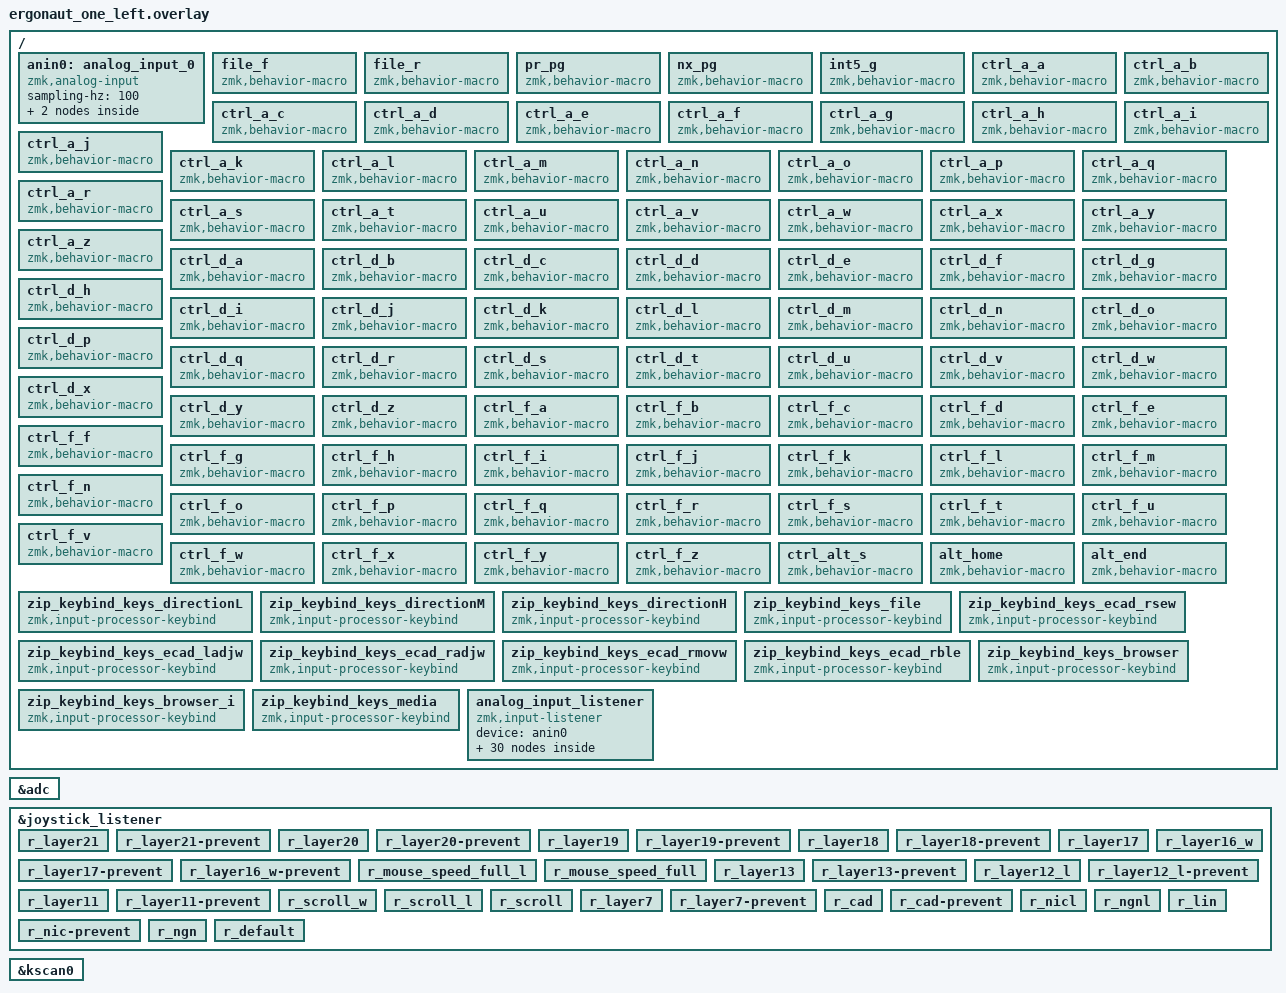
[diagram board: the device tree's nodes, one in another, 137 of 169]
/*
 * Copyright (c) 2020 The ZMK Contributors
 *
 * SPDX-License-Identifier: MIT
 */

#include "ergonaut_one.dtsi"
#include <zephyr/dt-bindings/input/input-event-codes.h>
#include <input/processors.dtsi>
#include <dt-bindings/zmk/input_transform.h>
#include <dt-bindings/zmk/keys.h>
#include <behaviors/naginata.dtsi>
#include <dt-bindings/zmk/pointing.h> // pointing.h はマウス機能に必要です
// #include <behaviors/input_gestures_accel.dtsi>

#define ZMK_POINTING_DEFAULT_MOVE_VAL 600   // default: 600
#define ZMK_POINTING_DEFAULT_SCRL_VAL 10    // default: 10

#define QWE 0
#define NGN 1
#define NIC 2
#define LIN 3
#define NGNL 4
#define NICL 5
#define CAD 6
#define WIN 7
#define LWR 8
#define LWRL 9
#define LWRW 10
#define RSE 11
#define RSEL 12
#define RSEW 13
#define ADJ 14
#define ADJL 15
#define ADJW 16
#define MOV 17
#define MOVL 18
#define MOVW 19
#define NUM 20
#define BLE 21

&adc {
	status = "okay";
};

/ {
	// 左のジョイスティック（マウスカーソル移動用）
	anin0: analog_input_0 {
		compatible = "zmk,analog-input";
		sampling-hz = <100>;
		y-ch {
			io-channels = <&adc 0>; // Y軸がADCチャンネル0に接続
			mv-mid = <1555>; // Y軸のニュートラル（中央）でのミリボルト値
			mv-min-max = <2615>; // Y軸の最小/最大ミリボルト範囲
			mv-deadzone = <88>; // Y軸のデッドゾーン（感度を調整）
			scale-multiplier = <1>; // スケーリングの乗数
			scale-divisor = <50>; // スケーリングの除数
			#invert; // Y軸の入力を反転
			evt-type = <INPUT_EV_REL>; // 相対イベントタイプ
			input-code = <INPUT_REL_Y>; // Y軸の動きをマウスのY軸（垂直）にマッピング
		};
		x-ch {
			io-channels = <&adc 1>; // X軸がADCチャンネル1に接続
			mv-mid = <1576>; // X軸のニュートラル（中央）でのミリボルト値
			mv-min-max = <2460>; // X軸の最小/最大ミリボルト範囲
			mv-deadzone = <88>; // X軸のデッドゾーン
			scale-multiplier = <1>;
			scale-divisor = <50>;
			invert; // X軸の入力を反転
			evt-type = <INPUT_EV_REL>;
			input-code = <INPUT_REL_X>; // X軸の動きをマウスのX軸（水平）にマッピング
			#report-on-change-only;
		};
	};
	
	file_f: file_f { // ファイルの切り替え正
		compatible = "zmk,behavior-macro";
		wait-ms = <40>;
		tap-ms = <40>;
		#binding-cells = <0>;
		bindings
			= <&macro_press &kp LCTRL>
			, <&macro_tap &kp F6>
			, <&macro_release &kp LCTRL>
			;
    };
	file_r: file_r { // ファイルの切り替え逆
		compatible = "zmk,behavior-macro";
		wait-ms = <40>;
		tap-ms = <40>;
		#binding-cells = <0>;
		bindings
			= <&macro_press &kp LSHFT>
			, <&macro_press &kp LCTRL>
			, <&macro_tap &kp F6>
			, <&macro_release &kp LCTRL>
			, <&macro_release &kp LSHFT>
			;
    };
	pr_pg: pr_pg { // 前ページ切り替え
		compatible = "zmk,behavior-macro";
		wait-ms = <40>;
		tap-ms = <40>;
		#binding-cells = <0>;
		bindings
			= <&macro_press &kp LSHFT>
			, <&macro_tap &kp F5>
			, <&macro_release &kp LSHFT>
			;
    };
	nx_pg: nx_pg { // 次ページ切り替え
		compatible = "zmk,behavior-macro";
		wait-ms = <40>;
		tap-ms = <40>;
		#binding-cells = <0>;
		bindings
			= <&macro_press &kp LSHFT>
			, <&macro_tap &kp F6>
			, <&macro_release &kp LSHFT>
			;
    };
	int5_g: int5_g { // 端点再設定(AHK)
		compatible = "zmk,behavior-macro";
		#binding-cells = <0>;
		bindings
			= <&macro_press &kp INT5>
			, <&macro_wait_time 40>
			, <&macro_tap &kp G>
			, <&macro_wait_time 40>
			, <&macro_release &kp INT5>
			;
    };

	// ここから下はECAD用マクロ定義
        // =========================================================================
        // --- 2. Ctrl + A (<Key1> + Ctrl + A) ---
        // =========================================================================
        
	// Ctrl + A, A: 回転
	ctrl_a_a: ctrl_a_a {
		compatible = "zmk,behavior-macro";
		#binding-cells = <0>;
		bindings
			= <&macro_press &kp LCTRL>
			, <&macro_tap &kp A>, <&macro_release &kp LCTRL>
			, <&macro_tap &kp A>
			;
	};

	// Ctrl + A, B: 長方形(サイズ)
	ctrl_a_b: ctrl_a_b {
		compatible = "zmk,behavior-macro";
		#binding-cells = <0>;
		bindings
			= <&macro_press &kp LCTRL>
			, <&macro_tap &kp A>, <&macro_release &kp LCTRL>
			, <&macro_tap &kp B>
			;
	};

	// Ctrl + A, C: コピー
	ctrl_a_c: ctrl_a_c {
		compatible = "zmk,behavior-macro";
		#binding-cells = <0>;
		bindings
			= <&macro_press &kp LCTRL>
			, <&macro_tap &kp A>, <&macro_release &kp LCTRL>
			, <&macro_tap &kp C>
			;
	};

	// Ctrl + A, D: 補助線削除
	ctrl_a_d: ctrl_a_d {
		compatible = "zmk,behavior-macro";
		#binding-cells = <0>;
		bindings
			= <&macro_press &kp LCTRL>
			, <&macro_tap &kp A>, <&macro_release &kp LCTRL>
			, <&macro_tap &kp D>
			;
	};

	// Ctrl + A, E: 文字種別変更
	ctrl_a_e: ctrl_a_e {
		compatible = "zmk,behavior-macro";
		#binding-cells = <0>;
		bindings
			= <&macro_press &kp LCTRL>
			, <&macro_tap &kp A>, <&macro_release &kp LCTRL>
			, <&macro_tap &kp E>
			;
	};

	// Ctrl + A, F: 多相結線
	ctrl_a_f: ctrl_a_f {
		compatible = "zmk,behavior-macro";
		#binding-cells = <0>;
		bindings
			= <&macro_press &kp LCTRL>
			, <&macro_tap &kp A>, <&macro_release &kp LCTRL>
			, <&macro_tap &kp F>
			;
	};

	// Ctrl + A, G: 図形グループ化解除
	ctrl_a_g: ctrl_a_g {
		compatible = "zmk,behavior-macro";
		#binding-cells = <0>;
		bindings
			= <&macro_press &kp LCTRL>
			, <&macro_tap &kp A>, <&macro_release &kp LCTRL>
			, <&macro_tap &kp G>
			;
	};

	// Ctrl + A, H: 文字列置換
	ctrl_a_h: ctrl_a_h {
		compatible = "zmk,behavior-macro";
		#binding-cells = <0>;
		bindings
			= <&macro_press &kp LCTRL>
			, <&macro_tap &kp A>, <&macro_release &kp LCTRL>
			, <&macro_tap &kp H>
			;
	};

	// Ctrl + A, I: 連続寸法線
	ctrl_a_i: ctrl_a_i {
		compatible = "zmk,behavior-macro";
		#binding-cells = <0>;
		bindings
			= <&macro_press &kp LCTRL>
			, <&macro_tap &kp A>, <&macro_release &kp LCTRL>
			, <&macro_tap &kp I>
			;
	};

	// Ctrl + A, J: 図面管理情報
	ctrl_a_j: ctrl_a_j {
		compatible = "zmk,behavior-macro";
		#binding-cells = <0>;
		bindings
			= <&macro_press &kp LCTRL>
			, <&macro_tap &kp A>, <&macro_release &kp LCTRL>
			, <&macro_tap &kp J>
			;
	};

	// Ctrl + A, K: コメント
	ctrl_a_k: ctrl_a_k {
		compatible = "zmk,behavior-macro";
		#binding-cells = <0>;
		bindings
			= <&macro_press &kp LCTRL>
			, <&macro_tap &kp A>, <&macro_release &kp LCTRL>
			, <&macro_tap &kp K>
			;
	};

	// Ctrl + A, L: 直線(中心線)
	ctrl_a_l: ctrl_a_l {
		compatible = "zmk,behavior-macro";
		#binding-cells = <0>;
		bindings
			= <&macro_press &kp LCTRL>
			, <&macro_tap &kp A>, <&macro_release &kp LCTRL>
			, <&macro_tap &kp L>
			;
	};

	// Ctrl + A, M: 上下中央間隔揃え
	ctrl_a_m: ctrl_a_m {
		compatible = "zmk,behavior-macro";
		#binding-cells = <0>;
		bindings
			= <&macro_press &kp LCTRL>
			, <&macro_tap &kp A>, <&macro_release &kp LCTRL>
			, <&macro_tap &kp M>
			;
	};

	// Ctrl + A, N: 自動線番範囲選択
	ctrl_a_n: ctrl_a_n {
		compatible = "zmk,behavior-macro";
		#binding-cells = <0>;
		bindings
			= <&macro_press &kp LCTRL>
			, <&macro_tap &kp A>, <&macro_release &kp LCTRL>
			, <&macro_tap &kp N>
			, <&macro_wait_time 80>
			, <&macro_tap &kp TAB>
			, <&macro_wait_time 50>
			, <&macro_tap &kp TAB>
			, <&macro_wait_time 50>
			, <&macro_tap &kp TAB>
			;
	};

	// Ctrl + A, O: 図形要素分解
	ctrl_a_o: ctrl_a_o {
		compatible = "zmk,behavior-macro";
		#binding-cells = <0>;
		bindings
			= <&macro_press &kp LCTRL>
			, <&macro_tap &kp A>, <&macro_release &kp LCTRL>
			, <&macro_tap &kp O>
			;
	};

	// Ctrl + A, P: ページ編集
	ctrl_a_p: ctrl_a_p {
		compatible = "zmk,behavior-macro";
		#binding-cells = <0>;
		bindings
			= <&macro_press &kp LCTRL>
			, <&macro_tap &kp A>, <&macro_release &kp LCTRL>
			, <&macro_tap &kp P>
			;
	};

	// Ctrl + A, Q: 円(中心)
	ctrl_a_q: ctrl_a_q {
		compatible = "zmk,behavior-macro";
		#binding-cells = <0>;
		bindings
			= <&macro_press &kp LCTRL>
			, <&macro_tap &kp A>, <&macro_release &kp LCTRL>
			, <&macro_tap &kp Q>
			;
	};

	// Ctrl + A, R: Ｒ枠変更
	ctrl_a_r: ctrl_a_r {
		compatible = "zmk,behavior-macro";
		#binding-cells = <0>;
		bindings
			= <&macro_press &kp LCTRL>
			, <&macro_tap &kp A>, <&macro_release &kp LCTRL>
			, <&macro_tap &kp R>
			;
	};

	// Ctrl + A, S: シンボル置換
	ctrl_a_s: ctrl_a_s {
		compatible = "zmk,behavior-macro";
		#binding-cells = <0>;
		bindings
			= <&macro_press &kp LCTRL>
			, <&macro_tap &kp A>, <&macro_release &kp LCTRL>
			, <&macro_tap &kp S>
			;
	};

	// Ctrl + A, T: 文章
	ctrl_a_t: ctrl_a_t {
		compatible = "zmk,behavior-macro";
		#binding-cells = <0>;
		bindings
			= <&macro_press &kp LCTRL>
			, <&macro_tap &kp A>, <&macro_release &kp LCTRL>
			, <&macro_tap &kp T>
			;
	};

	// Ctrl + A, U: 連続寸法線削除
	ctrl_a_u: ctrl_a_u {
		compatible = "zmk,behavior-macro";
		#binding-cells = <0>;
		bindings
			= <&macro_press &kp LCTRL>
			, <&macro_tap &kp A>, <&macro_release &kp LCTRL>
			, <&macro_tap &kp U>
			;
	};

	// Ctrl + A, V: 貼り付け
	ctrl_a_v: ctrl_a_v {
		compatible = "zmk,behavior-macro";
		#binding-cells = <0>;
		bindings
			= <&macro_press &kp LCTRL>
			, <&macro_tap &kp A>, <&macro_release &kp LCTRL>
			, <&macro_tap &kp V>
			;
	};

	// Ctrl + A, W: 渡りページ編集
	ctrl_a_w: ctrl_a_w {
		compatible = "zmk,behavior-macro";
		#binding-cells = <0>;
		bindings
			= <&macro_press &kp LCTRL>
			, <&macro_tap &kp A>, <&macro_release &kp LCTRL>
			, <&macro_tap &kp W>
			;
	};

	// Ctrl + A, X: 範囲切断
	ctrl_a_x: ctrl_a_x {
		compatible = "zmk,behavior-macro";
		#binding-cells = <0>;
		bindings
			= <&macro_press &kp LCTRL>
			, <&macro_tap &kp A>, <&macro_release &kp LCTRL>
			, <&macro_tap &kp X>
			;
	};

	// Ctrl + A, Y: シンボルレイヤ変更
	ctrl_a_y: ctrl_a_y {
		compatible = "zmk,behavior-macro";
		#binding-cells = <0>;
		bindings
			= <&macro_press &kp LCTRL>
			, <&macro_tap &kp A>, <&macro_release &kp LCTRL>
			, <&macro_tap &kp Y>
			;
	};

	// Ctrl + A, Z: フォーマット情報
	ctrl_a_z: ctrl_a_z {
		compatible = "zmk,behavior-macro";
		#binding-cells = <0>;
		bindings
			= <&macro_press &kp LCTRL>
			, <&macro_tap &kp A>, <&macro_release &kp LCTRL>
			, <&macro_tap &kp Z>
			;
	};


	// =========================================================================
	// --- 3. Ctrl + D (<Key1> + Ctrl + D) ---
	// =========================================================================

	// Ctrl + D, A: 拡大・縮小
	ctrl_d_a: ctrl_d_a {
		compatible = "zmk,behavior-macro";
		#binding-cells = <0>;
		bindings
			= <&macro_press &kp LCTRL>
			, <&macro_tap &kp D>, <&macro_release &kp LCTRL>
			, <&macro_tap &kp A>
			;
	};

	// Ctrl + D, B: 面取り
	ctrl_d_b: ctrl_d_b {
		compatible = "zmk,behavior-macro";
		#binding-cells = <0>;
		bindings
			= <&macro_press &kp LCTRL>
			, <&macro_tap &kp D>, <&macro_release &kp LCTRL>
			, <&macro_tap &kp B>
			;
	};

	// Ctrl + D, C: 円弧(中心)
	ctrl_d_c: ctrl_d_c {
		compatible = "zmk,behavior-macro";
		#binding-cells = <0>;
		bindings
			= <&macro_press &kp LCTRL>
			, <&macro_tap &kp D>, <&macro_release &kp LCTRL>
			, <&macro_tap &kp C>
			;
	};

	// Ctrl + D, D: 補助線全削除
	ctrl_d_d: ctrl_d_d {
		compatible = "zmk,behavior-macro";
		#binding-cells = <0>;
		bindings
			= <&macro_press &kp LCTRL>
			, <&macro_tap &kp D>, <&macro_release &kp LCTRL>
			, <&macro_tap &kp D>
			;
	};

	// Ctrl + D, E: 文章修正
	ctrl_d_e: ctrl_d_e {
		compatible = "zmk,behavior-macro";
		#binding-cells = <0>;
		bindings
			= <&macro_press &kp LCTRL>
			, <&macro_tap &kp D>, <&macro_release &kp LCTRL>
			, <&macro_tap &kp E>
			;
	};

	// Ctrl + D, F: ツイスト線
	ctrl_d_f: ctrl_d_f {
		compatible = "zmk,behavior-macro";
		#binding-cells = <0>;
		bindings
			= <&macro_press &kp LCTRL>
			, <&macro_tap &kp D>, <&macro_release &kp LCTRL>
			, <&macro_tap &kp F>
			;
	};

	// Ctrl + D, G: 図形配列
	ctrl_d_g: ctrl_d_g {
		compatible = "zmk,behavior-macro";
		#binding-cells = <0>;
		bindings
			= <&macro_press &kp LCTRL>
			, <&macro_tap &kp D>, <&macro_release &kp LCTRL>
			, <&macro_tap &kp G>
			;
	};

	// Ctrl + D, H: 文字列検索
	ctrl_d_h: ctrl_d_h {
		compatible = "zmk,behavior-macro";
		#binding-cells = <0>;
		bindings
			= <&macro_press &kp LCTRL>
			, <&macro_tap &kp D>, <&macro_release &kp LCTRL>
			, <&macro_tap &kp H>
			;
	};

	// Ctrl + D, I: 寸法線グループ化解除
	ctrl_d_i: ctrl_d_i {
		compatible = "zmk,behavior-macro";
		#binding-cells = <0>;
		bindings
			= <&macro_press &kp LCTRL>
			, <&macro_tap &kp D>, <&macro_release &kp LCTRL>
			, <&macro_tap &kp I>
			;
	};

	// Ctrl + D, J: ページ管理情報
	ctrl_d_j: ctrl_d_j {
		compatible = "zmk,behavior-macro";
		#binding-cells = <0>;
		bindings
			= <&macro_press &kp LCTRL>
			, <&macro_tap &kp D>, <&macro_release &kp LCTRL>
			, <&macro_tap &kp J>
			;
	};

	// Ctrl + D, K: 目次作成
	ctrl_d_k: ctrl_d_k {
		compatible = "zmk,behavior-macro";
		#binding-cells = <0>;
		bindings
			= <&macro_press &kp LCTRL>
			, <&macro_tap &kp D>, <&macro_release &kp LCTRL>
			, <&macro_tap &kp K>
			;
	};

	// Ctrl + D, L: 平行補助線入力
	ctrl_d_l: ctrl_d_l {
		compatible = "zmk,behavior-macro";
		#binding-cells = <0>;
		bindings
			= <&macro_press &kp LCTRL>
			, <&macro_tap &kp D>, <&macro_release &kp LCTRL>
			, <&macro_tap &kp L>
			;
	};

	// Ctrl + D, M: 左右中央間隔揃え
	ctrl_d_m: ctrl_d_m {
		compatible = "zmk,behavior-macro";
		#binding-cells = <0>;
		bindings
			= <&macro_press &kp LCTRL>
			, <&macro_tap &kp D>, <&macro_release &kp LCTRL>
			, <&macro_tap &kp M>
			;
	};

	// Ctrl + D, N: 三相線番
	ctrl_d_n: ctrl_d_n {
		compatible = "zmk,behavior-macro";
		#binding-cells = <0>;
		bindings
			= <&macro_press &kp LCTRL>
			, <&macro_tap &kp D>, <&macro_release &kp LCTRL>
			, <&macro_tap &kp N>
			;
	};

	// Ctrl + D, O: 図形要素分割
	ctrl_d_o: ctrl_d_o {
		compatible = "zmk,behavior-macro";
		#binding-cells = <0>;
		bindings
			= <&macro_press &kp LCTRL>
			, <&macro_tap &kp D>, <&macro_release &kp LCTRL>
			, <&macro_tap &kp O>
			;
	};

	// Ctrl + D, P: 印刷情報
	ctrl_d_p: ctrl_d_p {
		compatible = "zmk,behavior-macro";
		#binding-cells = <0>;
		bindings
			= <&macro_press &kp LCTRL>
			, <&macro_tap &kp D>, <&macro_release &kp LCTRL>
			, <&macro_tap &kp P>
			;
	};

	// Ctrl + D, Q: 雲形
	ctrl_d_q: ctrl_d_q {
		compatible = "zmk,behavior-macro";
		#binding-cells = <0>;
		bindings
			= <&macro_press &kp LCTRL>
			, <&macro_tap &kp D>, <&macro_release &kp LCTRL>
			, <&macro_tap &kp Q>
			;
	};

	// Ctrl + D, R: 接続点
	ctrl_d_r: ctrl_d_r {
		compatible = "zmk,behavior-macro";
		#binding-cells = <0>;
		bindings
			= <&macro_press &kp LCTRL>
			, <&macro_tap &kp D>, <&macro_release &kp LCTRL>
			, <&macro_tap &kp R>
			;
	};

	// Ctrl + D, S: DXF/DWGファイル入力
	ctrl_d_s: ctrl_d_s {
		compatible = "zmk,behavior-macro";
		#binding-cells = <0>;
		bindings
			= <&macro_press &kp LCTRL>
			, <&macro_tap &kp D>, <&macro_release &kp LCTRL>
			, <&macro_tap &kp S>
			;
	};

	// Ctrl + D, T: 製品情報
	ctrl_d_t: ctrl_d_t {
		compatible = "zmk,behavior-macro";
		#binding-cells = <0>;
		bindings
			= <&macro_press &kp LCTRL>
			, <&macro_tap &kp D>, <&macro_release &kp LCTRL>
			, <&macro_tap &kp T>
			;
	};

	// Ctrl + D, U: 寸法線グループ化
	ctrl_d_u: ctrl_d_u {
		compatible = "zmk,behavior-macro";
		#binding-cells = <0>;
		bindings
			= <&macro_press &kp LCTRL>
			, <&macro_tap &kp D>, <&macro_release &kp LCTRL>
			, <&macro_tap &kp U>
			;
	};

	// Ctrl + D, V: 盤枠線(矩形)
	ctrl_d_v: ctrl_d_v {
		compatible = "zmk,behavior-macro";
		#binding-cells = <0>;
		bindings
			= <&macro_press &kp LCTRL>
			, <&macro_tap &kp D>, <&macro_release &kp LCTRL>
			, <&macro_tap &kp V>
			;
	};

	// Ctrl + D, W: 一時補助線全削除
	ctrl_d_w: ctrl_d_w {
		compatible = "zmk,behavior-macro";
		#binding-cells = <0>;
		bindings
			= <&macro_press &kp LCTRL>
			, <&macro_tap &kp D>, <&macro_release &kp LCTRL>
			, <&macro_tap &kp W>
			;
	};

	// Ctrl + D, X: 長円
	ctrl_d_x: ctrl_d_x {
		compatible = "zmk,behavior-macro";
		#binding-cells = <0>;
		bindings
			= <&macro_press &kp LCTRL>
			, <&macro_tap &kp D>, <&macro_release &kp LCTRL>
			, <&macro_tap &kp X>
			;
	};

	// Ctrl + D, Y: 引出寸法線
	ctrl_d_y: ctrl_d_y {
		compatible = "zmk,behavior-macro";
		#binding-cells = <0>;
		bindings
			= <&macro_press &kp LCTRL>
			, <&macro_tap &kp D>, <&macro_release &kp LCTRL>
			, <&macro_tap &kp Y>
			;
	};

	// Ctrl + D, Z: 図面種別情報
	ctrl_d_z: ctrl_d_z {
		compatible = "zmk,behavior-macro";
		#binding-cells = <0>;
		bindings
			= <&macro_press &kp LCTRL>
			, <&macro_tap &kp D>, <&macro_release &kp LCTRL>
			, <&macro_tap &kp Z>
			;
	};


	// =========================================================================
	// --- 4. Ctrl + F (<Key1> + Ctrl + F) ---
	// =========================================================================
	
	// Ctrl + F, A: 未設定
	ctrl_f_a: ctrl_f_a {
		compatible = "zmk,behavior-macro";
		#binding-cells = <0>;
		bindings
			= <&macro_press &kp LCTRL>
			, <&macro_tap &kp F>, <&macro_release &kp LCTRL>
			, <&macro_tap &kp A>
			;
	};

	// Ctrl + F, B: 正方形(一辺)
	ctrl_f_b: ctrl_f_b {
		compatible = "zmk,behavior-macro";
		#binding-cells = <0>;
		bindings
			= <&macro_press &kp LCTRL>
			, <&macro_tap &kp F>, <&macro_release &kp LCTRL>
			, <&macro_tap &kp B>
			;
	};

	// Ctrl + F, C: 銘板表編集
	ctrl_f_c: ctrl_f_c {
		compatible = "zmk,behavior-macro";
		#binding-cells = <0>;
		bindings
			= <&macro_press &kp LCTRL>
			, <&macro_tap &kp F>, <&macro_release &kp LCTRL>
			, <&macro_tap &kp C>
			;
	};

	// Ctrl + F, D: 銘板表
	ctrl_f_d: ctrl_f_d {
		compatible = "zmk,behavior-macro";
		#binding-cells = <0>;
		bindings
			= <&macro_press &kp LCTRL>
			, <&macro_tap &kp F>, <&macro_release &kp LCTRL>
			, <&macro_tap &kp D>
			;
	};

	// Ctrl + F, E: 閉じる
	ctrl_f_e: ctrl_f_e {
		compatible = "zmk,behavior-macro";
		#binding-cells = <0>;
		bindings
			= <&macro_press &kp LCTRL>
			, <&macro_tap &kp F>, <&macro_release &kp LCTRL>
			, <&macro_tap &kp E>
			;
	};

	// Ctrl + F, F: 未設定
	ctrl_f_f: ctrl_f_f {
		compatible = "zmk,behavior-macro";
		#binding-cells = <0>;
		bindings
			= <&macro_press &kp LCTRL>
			, <&macro_tap &kp F>, <&macro_release &kp LCTRL>
			, <&macro_tap &kp F>
			;
	};

	// Ctrl + F, G: 部品表編集
	ctrl_f_g: ctrl_f_g {
		compatible = "zmk,behavior-macro";
		#binding-cells = <0>;
		bindings
			= <&macro_press &kp LCTRL>
			, <&macro_tap &kp F>, <&macro_release &kp LCTRL>
			, <&macro_tap &kp G>
			;
	};

	// Ctrl + F, H: 集計表
	ctrl_f_h: ctrl_f_h {
		compatible = "zmk,behavior-macro";
		#binding-cells = <0>;
		bindings
			= <&macro_press &kp LCTRL>
			, <&macro_tap &kp F>, <&macro_release &kp LCTRL>
			, <&macro_tap &kp H>
			;
	};

	// Ctrl + F, I: 上揃え
	ctrl_f_i: ctrl_f_i {
		compatible = "zmk,behavior-macro";
		#binding-cells = <0>;
		bindings
			= <&macro_press &kp LCTRL>
			, <&macro_tap &kp F>, <&macro_release &kp LCTRL>
			, <&macro_tap &kp I>
			;
	};

	// Ctrl + F, J: 左揃え
	ctrl_f_j: ctrl_f_j {
		compatible = "zmk,behavior-macro";
		#binding-cells = <0>;
		bindings
			= <&macro_press &kp LCTRL>
			, <&macro_tap &kp F>, <&macro_release &kp LCTRL>
			, <&macro_tap &kp J>
			;
	};

	// Ctrl + F, K: 下揃え
	ctrl_f_k: ctrl_f_k {
		compatible = "zmk,behavior-macro";
		#binding-cells = <0>;
		bindings
			= <&macro_press &kp LCTRL>
			, <&macro_tap &kp F>, <&macro_release &kp LCTRL>
			, <&macro_tap &kp K>
			;
	};

	// Ctrl + F, L: 右揃え
	ctrl_f_l: ctrl_f_l {
		compatible = "zmk,behavior-macro";
		#binding-cells = <0>;
		bindings
			= <&macro_press &kp LCTRL>
			, <&macro_tap &kp F>, <&macro_release &kp LCTRL>
			, <&macro_tap &kp L>
			;
	};

	// Ctrl + F, M: 従属文字位置変更
	ctrl_f_m: ctrl_f_m {
		compatible = "zmk,behavior-macro";
		#binding-cells = <0>;
		bindings
			= <&macro_press &kp LCTRL>
			, <&macro_tap &kp F>, <&macro_release &kp LCTRL>
			, <&macro_tap &kp M>
			;
	};

	// Ctrl + F, N: 未設定
	ctrl_f_n: ctrl_f_n {
		compatible = "zmk,behavior-macro";
		#binding-cells = <0>;
		bindings
			= <&macro_press &kp LCTRL>
			, <&macro_tap &kp F>, <&macro_release &kp LCTRL>
			, <&macro_tap &kp N>
			;
	};

	// Ctrl + F, O: 上下中央揃え
	ctrl_f_o: ctrl_f_o {
		compatible = "zmk,behavior-macro";
		#binding-cells = <0>;
		bindings
			= <&macro_press &kp LCTRL>
			, <&macro_tap &kp F>, <&macro_release &kp LCTRL>
			, <&macro_tap &kp O>
			;
	};

	// Ctrl + F, P: 印刷
	ctrl_f_p: ctrl_f_p {
		compatible = "zmk,behavior-macro";
		#binding-cells = <0>;
		bindings
			= <&macro_press &kp LCTRL>
			, <&macro_tap &kp F>, <&macro_release &kp LCTRL>
			, <&macro_tap &kp P>
			;
	};

	// Ctrl + F, Q: 未設定
	ctrl_f_q: ctrl_f_q {
		compatible = "zmk,behavior-macro";
		#binding-cells = <0>;
		bindings
			= <&macro_press &kp LCTRL>
			, <&macro_tap &kp F>, <&macro_release &kp LCTRL>
			, <&macro_tap &kp Q>
			;
	};

	// Ctrl + F, R: 未設定
	ctrl_f_r: ctrl_f_r {
		compatible = "zmk,behavior-macro";
		#binding-cells = <0>;
		bindings
			= <&macro_press &kp LCTRL>
			, <&macro_tap &kp F>, <&macro_release &kp LCTRL>
			, <&macro_tap &kp R>
			;
	};

	// Ctrl + F, S: 上書き保存
	ctrl_f_s: ctrl_f_s {
		compatible = "zmk,behavior-macro";
		#binding-cells = <0>;
		bindings
			= <&macro_press &kp LCTRL>
			, <&macro_tap &kp F>, <&macro_release &kp LCTRL>
			, <&macro_tap &kp S>
			;
	};

	// Ctrl + F, T: 未設定
	ctrl_f_t: ctrl_f_t {
		compatible = "zmk,behavior-macro";
		#binding-cells = <0>;
		bindings
			= <&macro_press &kp LCTRL>
			, <&macro_tap &kp F>, <&macro_release &kp LCTRL>
			, <&macro_tap &kp T>
			;
	};

	// Ctrl + F, U: 左右中央揃え
	ctrl_f_u: ctrl_f_u {
		compatible = "zmk,behavior-macro";
		#binding-cells = <0>;
		bindings
			= <&macro_press &kp LCTRL>
			, <&macro_tap &kp F>, <&macro_release &kp LCTRL>
			, <&macro_tap &kp U>
			;
	};

	// Ctrl + F, V: 盤枠製品番号
	ctrl_f_v: ctrl_f_v {
		compatible = "zmk,behavior-macro";
		#binding-cells = <0>;
		bindings
			= <&macro_press &kp LCTRL>
			, <&macro_tap &kp F>, <&macro_release &kp LCTRL>
			, <&macro_tap &kp V>
			;
	};

	// Ctrl + F, W: 未設定
	ctrl_f_w: ctrl_f_w {
		compatible = "zmk,behavior-macro";
		#binding-cells = <0>;
		bindings
			= <&macro_press &kp LCTRL>
			, <&macro_tap &kp F>, <&macro_release &kp LCTRL>
			, <&macro_tap &kp W>
			;
	};

	// Ctrl + F, X: 未設定
	ctrl_f_x: ctrl_f_x {
		compatible = "zmk,behavior-macro";
		#binding-cells = <0>;
		bindings
			= <&macro_press &kp LCTRL>
			, <&macro_tap &kp F>, <&macro_release &kp LCTRL>
			, <&macro_tap &kp X>
			;
	};

	// Ctrl + F, Y: 未設定
	ctrl_f_y: ctrl_f_y {
		compatible = "zmk,behavior-macro";
		#binding-cells = <0>;
		bindings
			= <&macro_press &kp LCTRL>
			, <&macro_tap &kp F>, <&macro_release &kp LCTRL>
			, <&macro_tap &kp Y>
			;
	};

	// Ctrl + F, Z: 未設定
	ctrl_f_z: ctrl_f_z {
		compatible = "zmk,behavior-macro";
		#binding-cells = <0>;
		bindings
			= <&macro_press &kp LCTRL>
			, <&macro_tap &kp F>, <&macro_release &kp LCTRL>
			, <&macro_tap &kp Z>
			;
	};

	// ECAD用マクロ定義ここまで

	ctrl_alt_s: ctrl_alt_s { // シンボル一覧(AHK)
		compatible = "zmk,behavior-macro";
		#binding-cells = <0>;
		bindings
			= <&macro_press &kp LCTRL>
			// , <&macro_wait_time 40>
			, <&macro_press &kp LALT>
			, <&macro_tap &kp S>
			, <&macro_release &kp LALT>
			// , <&macro_wait_time 40>
			, <&macro_release &kp LCTRL>
			// , <&to WIN> // ADJWのベースレイヤー（例としてWINレイヤー）に戻る※rsewレイヤロック強制解除用
			;
	};	
	alt_home: alt_home { // 移動左90度回転[AHK]
		compatible = "zmk,behavior-macro";
		#binding-cells = <0>;
		bindings
			= <&macro_press &kp LALT>
			, <&macro_tap &kp HOME>
			, <&macro_release &kp LALT>
			;
    };
	alt_end: alt_end { // 移動右90度回転[AHK]
		compatible = "zmk,behavior-macro";
		#binding-cells = <0>;
		bindings
			= <&macro_press &kp LALT>
			, <&macro_tap &kp END>
			, <&macro_release &kp LALT>
			;
    };

	zip_keybind_keys_directionL: zip_keybind_keys_directionL {
			compatible = "zmk,input-processor-keybind";
			#input-processor-cells = <0>;
		track_remainders;
			bindings = <&kp RIGHT>
					  ,<&kp LEFT>
					  ,<&kp UP>
					  ,<&kp DOWN>
					  ;
			tick = <150>;
			wait-ms = <100>;
			tap-ms = <50>;
			mode = <1>;
	};
	zip_keybind_keys_directionM: zip_keybind_keys_directionM {
			compatible = "zmk,input-processor-keybind";
			#input-processor-cells = <0>;
		track_remainders;
			bindings = <&kp RIGHT>
					 , <&kp LEFT>
					 , <&kp UP>
					 , <&kp DOWN>
					 ;
			tick = <100>; // ティック間隔
			wait-ms = <5>; // 待機時間
			tap-ms = <40>; // タップ時間
	};
	zip_keybind_keys_directionH: zip_keybind_keys_directionH {
			compatible = "zmk,input-processor-keybind";
			#input-processor-cells = <0>;
		// track_remainders;
			bindings = <&kp RIGHT>
					  ,<&kp LEFT>
					  ,<&kp UP>
					  ,<&kp DOWN>
					  ;
			tick = <50>; // ティック間隔
			wait-ms = <0>; // 待機時間
			tap-ms = <50>; // タップ時間
	};
	zip_keybind_keys_file: zip_keybind_keys_file {
			compatible = "zmk,input-processor-keybind";
			#input-processor-cells = <0>;
		track_remainders;
			bindings = <&nx_pg>  // 右：次ページ切り替え
					 , <&pr_pg>  // 左：前ページ切り替え
					 , <&file_r> // 上：ファイルの切り替え逆
					 , <&file_f> // 下：ファイルの切り替え正
					 ;
			tick = <150>;
			wait-ms = <100>;
			tap-ms = <50>;
			mode = <1>;
    };
	zip_keybind_keys_ecad_rsew: zip_keybind_keys_ecad_rsew {
			compatible = "zmk,input-processor-keybind";
			#input-processor-cells = <0>;
		// track_remainders;
			bindings = <&kp C>  // 右：複写
	                 , <&kp D>  // 左：削除
					 , <&kp A>  // 上：領域移動
	                 , <&kp Z>  // 下：属性変更
					 ;
			tick = <120>; 		// 入力が継続している際、次のキー入力を発生させるまでの周期（間隔）
			wait-ms = <0>; 	// 入力を検知してから、実際に最初のキー（tap-msの開始）を押し下げるまでの遅延時間
			tap-ms = <50>; 		// キーを「押し下げている（Down）」状態の時間
			mode = <1>; 		// 通常、このモード指定は「蓄積された移動量（remainder）を考慮するかどうか」などの挙動を制御
    };
	zip_keybind_keys_ecad_ladjw: zip_keybind_keys_ecad_ladjw {
			compatible = "zmk,input-processor-keybind";
			#input-processor-cells = <0>;
		track_remainders;
			bindings = <&kp E>     // 右：文字修正
	                 , <&kp T>     // 左：文字
					 , <&ctrl_a_e> // 上：文字種別変更
					 , <&ctrl_d_e> // 下：文章修正
					 ;
			tick = <150>;
			wait-ms = <100>;
			tap-ms = <50>;
			mode = <1>;
    };
	zip_keybind_keys_ecad_radjw: zip_keybind_keys_ecad_radjw {
			compatible = "zmk,input-processor-keybind";
			#input-processor-cells = <0>;
		// track_remainders;
			bindings = <&ctrl_a_w>     // 右：渡りページ編集
	                 , <&kp R>         // 左：リファレンス編集
					 , <&ctrl_a_n>     // 上：自動線番範囲選択
					 , <&ctrl_alt_s>   // 下：シンボル一覧[AHK]
					 ;
			tick = <120>; 		// 入力が継続している際、次のキー入力を発生させるまでの周期（間隔）
			wait-ms = <0>; 	// 入力を検知してから、実際に最初のキー（tap-msの開始）を押し下げるまでの遅延時間
			tap-ms = <50>; 		// キーを「押し下げている（Down）」状態の時間
			mode = <1>; 		// 通常、このモード指定は「蓄積された移動量（remainder）を考慮するかどうか」などの挙動を制御
    };
	zip_keybind_keys_ecad_rmovw: zip_keybind_keys_ecad_rmovw {
			compatible = "zmk,input-processor-keybind";
			#input-processor-cells = <0>;
		// track_remainders;
			bindings = <&kp G>     // 右：図形グループ化
					 , <&ctrl_a_g> // 左：図形グループ化解除
	                 , <&kp W>     // 上：図形情報表示
					 , <&ctrl_a_d> // 下：補助線削除
					 ;
			tick = <120>; 		// 入力が継続している際、次のキー入力を発生させるまでの周期（間隔）
			wait-ms = <0>; 	// 入力を検知してから、実際に最初のキー（tap-msの開始）を押し下げるまでの遅延時間
			tap-ms = <50>; 		// キーを「押し下げている（Down）」状態の時間
			mode = <1>; 		// 通常、このモード指定は「蓄積された移動量（remainder）を考慮するかどうか」などの挙動を制御
    };
	zip_keybind_keys_ecad_rble: zip_keybind_keys_ecad_rble {
			compatible = "zmk,input-processor-keybind";
			#input-processor-cells = <0>;
		// track_remainders;
			bindings = <&ctrl_a_p> // 右：ページ編集
					 , <&kp P> 	   // 左：全ページ情報
	                 , <&ctrl_a_j> // 上：図面管理情報
	                 , <&ctrl_d_j> // 下：ページ管理情報
					 ;
			tick = <120>; 		// 入力が継続している際、次のキー入力を発生させるまでの周期（間隔）
			wait-ms = <0>; 	// 入力を検知してから、実際に最初のキー（tap-msの開始）を押し下げるまでの遅延時間
			tap-ms = <50>; 		// キーを「押し下げている（Down）」状態の時間
			mode = <1>; 		// 通常、このモード指定は「蓄積された移動量（remainder）を考慮するかどうか」などの挙動を制御
    };
	zip_keybind_keys_browser: zip_keybind_keys_browser {
			compatible = "zmk,input-processor-keybind";
			#input-processor-cells = <0>;
		track_remainders;
			bindings = <&kp LC(ENTER)> // 右：新しいタブで開く
	                 , <&kp LC(W)>     // 左：タブを閉じる
					 , <&kp LS(TAB)>   // 上：前の項目へ戻る
	                 , <&kp TAB>       // 下：次の項目へ進む
					 ;
			tick = <150>;
			wait-ms = <100>;
			tap-ms = <50>;
			mode = <1>;
    };
	zip_keybind_keys_browser_i: zip_keybind_keys_browser_i {
			compatible = "zmk,input-processor-keybind";
			#input-processor-cells = <0>;
		track_remainders;
			bindings = <&kp LG(T)>     // 右：新規タブを開く
	                 , <&kp LG(W)>     // 左：タブを閉じる
					 , <&kp LS(SPACE)> // 上：上へ戻る
	                 , <&kp SPACE>     // 下：下へ進む
					 ;
			tick = <150>;
			wait-ms = <100>;
			tap-ms = <50>;
			mode = <1>;
    };
	zip_keybind_keys_media: zip_keybind_keys_media {
			compatible = "zmk,input-processor-keybind";
			#input-processor-cells = <0>;
		track_remainders;
			bindings = <&kp C_FF>     // 右：早送り
					  ,<&kp C_RW>     // 左：巻き戻し
					  ,<&kp C_VOL_UP> // 上：音量アップ
					  ,<&kp C_VOL_DN> // 下：音量ダウン
					  ;
			tick = <60>;
			wait-ms = <0>;
			tap-ms = <10>;
	};

	// behaviors {
		// rrsew_right: input_right {
		// 		compatible = "zmk,behavior-mod-morph";
		// 		#binding-cells = <0>;
		// 		bindings = <&kp C>, <&kp LA(END)>; // 右：複写／移動右90度回転[AHK]
		// 		mods = <(MOD_LSFT|MOD_RSFT)>;
		// };
		// rrsew_left: input_left {
		// 		compatible = "zmk,behavior-mod-morph";
		// 		#binding-cells = <0>;
		// 		bindings = <&kp D>, <&kp LA(HOME)>; // 左：削除／移動左90度回転[AHK]
		// 		mods = <(MOD_LSFT|MOD_RSFT)>;
		// };
		// rrsew_up: input_up {
		// 		compatible = "zmk,behavior-mod-morph";
		// 		#binding-cells = <0>;
		// 		bindings = <&kp A>, <&ctrl_a_c>; // 上：領域移動／コピー[ctrl+a+c]
		// 		mods = <(MOD_LSFT|MOD_RSFT)>;// 上：領域移動
		// };
		// rrsew_down: input_down {
		// 		compatible = "zmk,behavior-mod-morph";
		// 		#binding-cells = <0>;
		// 		bindings = <&kp Z>, <&ctrl_a_v>; // 下：属性変更／貼付け[ctrl+a+v]
		// 		mods = <(MOD_LSFT|MOD_RSFT)>;
		// };
		// radjw_right: radjw_right {
		// 		compatible = "zmk,behavior-mod-morph";
		// 		#binding-cells = <0>;
		// 		bindings = <&ctrl_d_f>, <&ctrl_d_w>; // 右：多相結線／渡りページ編集
		// 		mods = <(MOD_LSFT|MOD_RSFT)>;
		// };
		// radjw_left: radjw_left {
		// 		compatible = "zmk,behavior-mod-morph";
		// 		#binding-cells = <0>;
		// 		bindings = <&ctrl_f_n>, <&ctrl_d_r>; // 左：三相線番／リファレンス編集
		// 		mods = <(MOD_LSFT|MOD_RSFT)>;
		// };
		// radjw_up: radjw_up {
		// 		compatible = "zmk,behavior-mod-morph";
		// 		#binding-cells = <0>;
		// 		bindings = <&ctrl_d_n>, <&ctrl_f_r>; // 上：自動線番／R枠変更
		// 		mods = <(MOD_LSFT|MOD_RSFT)>;// 上：領域移動
		// };
		// radjw_down: radjw_down {
		// 		compatible = "zmk,behavior-mod-morph";
		// 		#binding-cells = <0>;
		// 		bindings = <&ctrl_d_a>, <&ctrl_alt_s>; // 下：ツイスト線／シンボル一覧[AHK]
		// 		mods = <(MOD_LSFT|MOD_RSFT)>;
		// };
	// };

	analog_input_listener {
		status = "okay";
		compatible = "zmk,input-listener";
		device = <&anin0>; // 左のアナログ入力デバイス (anin0) を監視
		l_layer21 {
			layers = <BLE>; // レイヤー21がアクティブな場合
			input-processors = <&zip_keybind_keys_media>; // zip_keybind_keys_media を使用
			process-next; // 他のプロセッサも処理を継続
		};
		l_layer21-prevent {
			layers = <BLE>; // レイヤー21がアクティブな場合
			input-processors = <&zip_xy_scaler 0 1>; // ジョイスティックの動きをゼロにスケーリング（無効化）
		};
		l_layer20 {
			layers = <NUM>; // レイヤー20がアクティブな場合
			input-processors = <&zip_keybind_keys_file>; // zip_keybind_keys_file を使用
			process-next; // 他のプロセッサも処理を継続
		};
		l_layer20-prevent {
			layers = <NUM>; // レイヤー20がアクティブな場合
			input-processors = <&zip_xy_scaler 0 1>; // ジョイスティックの動きをゼロにスケーリング（無効化）
		};
		l_layer19 {
			layers = <MOVW>; // レイヤー19がアクティブな場合
			input-processors = <&zip_keybind_keys_browser>; // zip_keybind_keys_browser を使用 (ECAD用)
			process-next; // 他のプロセッサも処理を継続
		};
		l_layer19-prevent {
			layers = <MOVW>; // レイヤー19がアクティブな場合
			input-processors = <&zip_xy_scaler 0 1>; // ジョイスティックの動きをゼロにスケーリング（無効化）
		};
		l_layer18 {
			layers = <MOVL>; // レイヤー18がアクティブな場合
			input-processors = <&zip_keybind_keys_browser>; // zip_keybind_keys_browser を使用 (ECAD用)
			process-next; // 他のプロセッサも処理を継続
		};
		l_layer18-prevent {
			layers = <MOVL>; // レイヤー18がアクティブな場合
			input-processors = <&zip_xy_scaler 0 1>; // ジョイスティックの動きをゼロにスケーリング（無効化）
		};
		l_layer17 {
			layers = <MOV>; // レイヤー17がアクティブな場合
			input-processors = <&zip_keybind_keys_browser_i>; // zip_keybind_keys_browser_i を使用
			process-next; // 他のプロセッサも処理を継続
		};
		l_layer17-prevent {
			layers = <MOV>; // レイヤー17がアクティブな場合
			input-processors = <&zip_xy_scaler 0 1>; // ジョイスティックの動きをゼロにスケーリング（無効化）
		};		
		l_layer16 {
			layers = <ADJW>; // レイヤー16がアクティブな場合
			input-processors = <&zip_keybind_keys_ecad_ladjw>; // zip_keybind_keys_ladjw を使用
			process-next;
		};
		l_layer16-prevent {
			layers = <ADJW>; // レイヤー16がアクティブな場合
			input-processors = <&zip_xy_scaler 0 1>; // ジョイスティックの動きをゼロにスケーリング（無効化）
		};
		l_layer15 {
			layers = <ADJL>; // レイヤー15がアクティブな場合
			input-processors = <&zip_keybind_keys_directionH>; // zip_keybind_keys_directionH を使用
			process-next;
		};
		l_layer15-prevent {
			layers = <ADJL>; // レイヤー15がアクティブな場合
			input-processors = <&zip_xy_scaler 0 1>; // ジョイスティックの動きをゼロにスケーリング（無効化）
		};
		l_layer14 {
			layers = <ADJ>; // レイヤー14がアクティブな場合
			input-processors = <&zip_keybind_keys_directionH>; // zip_keybind_keys_directionH を使用
			process-next;
		};
		l_layer14-prevent {
			layers = <ADJ>; // レイヤー14がアクティブな場合
			input-processors = <&zip_xy_scaler 0 1>; // ジョイスティックの動きをゼロにスケーリング（無効化）
		};
		l_scroll_w {
			layers = <RSEW>; // レイヤー13がアクティブな場合
			input-processors = <&zip_xy_transform (INPUT_TRANSFORM_Y_INVERT)> // Y反転
							 , <&zip_xy_scaler 32 100> // スケーリング（32/100）
							 , <&zip_xy_to_scroll_mapper>; // スクロールイベントにマッピング
		};
		l_scroll_l {
			layers = <RSEL>; // レイヤー12がアクティブな場合
			input-processors = <&zip_xy_transform (INPUT_TRANSFORM_Y_INVERT)> // Y反転
							 , <&zip_xy_scaler 32 100> // スケーリング（32/100）
							 , <&zip_xy_to_scroll_mapper>; // スクロールイベントにマッピング
		};
		l_scroll {
			layers = <RSE>; // レイヤー11がアクティブな場合
			input-processors = <&zip_xy_transform (INPUT_TRANSFORM_Y_INVERT)> // Y反転
							 , <&zip_xy_scaler 16 100> // スケーリング（16/100）
							 , <&zip_xy_to_scroll_mapper>; // スクロールイベントにマッピング
		};
		l_mouse_speed_half_w {
			layers = <LWRW>; // レイヤー10がアクティブな場合
			input-processors = <&zip_xy_transform (0)> // 変換なし (Y軸反転を無効化)
							 , <&zip_xy_scaler 40 100>; // 速度を40/100に設定 (乗数40, 除数100)
		};
		l_mouse_speed_half_l {
			layers = <LWRL>; // レイヤー9がアクティブな場合
			input-processors = <&zip_xy_transform (0)> // 変換なし (Y軸反転を無効化)
							 , <&zip_xy_scaler 40 100>; // 速度を40/100に設定 (乗数40, 除数100)
		};
		l_mouse_speed_ipad {
			layers = <LWR>; // レイヤー8がアクティブな場合
			input-processors = <&zip_xy_transform (0)> // 変換なし (Y軸反転を無効化)
							 , <&zip_xy_scaler 40 100>; // 速度を40/100に設定 (乗数40, 除数100)
		};
		l_mouse_speed_win {
			layers = <WIN>; // レイヤー7がアクティブな場合
			input-processors = <&zip_xy_transform (0)> // 変換なし (Y軸反転を無効化)
							 , <&zip_xy_scaler 90 100>; // 速度を90/100に設定 (乗数90, 除数100)
		};
		l_mouse_speed_cad {
			layers = <CAD>; // レイヤー6がアクティブな場合
			input-processors = <&zip_xy_transform (0)> // 変換なし (Y軸反転を無効化)
							 , <&zip_xy_scaler 95 100>; // 速度を95/100に設定 (乗数95, 除数100)
		};
		l_mouse_speed_nicl {
			layers = <NICL>; // レイヤー5がアクティブな場合
			input-processors = <&zip_xy_transform (0)> // 変換なし (Y軸反転を無効化)
							 , <&zip_xy_scaler 100 100>; // 速度を100/100に設定 (乗数100, 除数100)
		};
		l_mouse_speed_ngnl {
			layers = <NGNL>; // レイヤー4がアクティブな場合
			input-processors = <&zip_xy_transform (0)> // 変換なし (Y軸反転を無効化)
							 , <&zip_xy_scaler 100 100>; // 速度を100/100に設定 (乗数100, 除数100)
		};
		l_mouse_speed_lin {
			layers = <LIN>; // レイヤー3がアクティブな場合
			input-processors = <&zip_xy_transform (0)> // 変換なし (Y軸反転を無効化)
							 , <&zip_xy_scaler 100 100>; // 速度を100/100に設定 (乗数100, 除数100)
		};
		// l_mouse_speed_full_nic {
		// 	layers = <NIC>; // レイヤー2がアクティブな場合
		// 	input-processors = <&zip_xy_transform (0)> // 変換なし (Y軸反転を無効化)
		// 					 , <&zip_xy_scaler 100 100>; // 速度を100/100に設定 (乗数100, 除数100)
		// };
		l_mouse_speed_full_nic-prevent {
			layers = <NIC>; // レイヤー2がアクティブな場合
			input-processors = <&zip_xy_scaler 0 1>; // ジョイスティックの動きをゼロにスケーリング（無効化）
		};
		l_mouse_speed_full_ngn {
			layers = <NGN>; // レイヤー1がアクティブな場合
			input-processors = <&zip_xy_transform (0)> // 変換なし (Y軸反転を無効化)
							 , <&zip_xy_scaler 100 100>; // 速度を100/100に設定 (乗数100, 除数100)
		};
		l_mouse_speed_full {
			layers = <QWE>; // レイヤー0（デフォルト）がアクティブな場合
			input-processors = <&zip_xy_transform (0)> // 変換なし (Y軸反転を無効化)
							 , <&zip_xy_scaler 100 100>; // 速度を100/100に設定 (乗数100, 除数100)
		};
	};
};

&joystick_listener {
		status = "okay";
		r_layer21 {
			layers = <BLE>; // レイヤー21がアクティブな場合
			input-processors = <&zip_keybind_keys_ecad_rble>; // zip_keybind_keys_ecad_rble を使用
			process-next; // 他のプロセッサも処理を継続
		};
		r_layer21-prevent {
			layers = <BLE>; // レイヤー21がアクティブな場合
			input-processors = <&zip_xy_scaler 0 1>; // ジョイスティックの動きをゼロにスケーリング（無効化）
		};
		r_layer20 {
			layers = <NUM>; // レイヤー20がアクティブな場合
			input-processors = <&zip_keybind_keys_directionL>; // zip_keybind_keys_directionL を使用
			process-next; // 他のプロセッサも処理を継続
		};
		r_layer20-prevent {
			layers = <NUM>; // レイヤー20がアクティブな場合
			input-processors = <&zip_xy_scaler 0 1>; // ジョイスティックの動きをゼロにスケーリング（無効化）
		};
		r_layer19 {
			layers = <MOVW>; // レイヤー19がアクティブな場合
			input-processors = <&zip_keybind_keys_ecad_rmovw>; // zip_keybind_keys_ecad_rmovw を使用
			process-next; // 他のプロセッサも処理を継続
		};
		r_layer19-prevent {
			layers = <MOVW>; // レイヤー19がアクティブな場合
			input-processors = <&zip_xy_scaler 0 1>; // ジョイスティックの動きをゼロにスケーリング（無効化）
		};
		r_layer18 {
			layers = <MOVL>; // レイヤー18がアクティブな場合
			input-processors = <&zip_keybind_keys_directionM>; // zip_keybind_keys_directionM を使用
			process-next; // 他のプロセッサも処理を継続
		};
		r_layer18-prevent {
			layers = <MOVL>; // レイヤー18がアクティブな場合
			input-processors = <&zip_xy_scaler 0 1>; // ジョイスティックの動きをゼロにスケーリング（無効化）
		};
		r_layer17 {
			layers = <MOV>; // レイヤー17がアクティブな場合
			input-processors = <&zip_keybind_keys_directionM>; // zip_keybind_keys_directionM を使用
			process-next; // 他のプロセッサも処理を継続
		};
		r_layer17-prevent {
			layers = <MOV>; // レイヤー17がアクティブな場合
			input-processors = <&zip_xy_scaler 0 1>; // ジョイスティックの動きをゼロにスケーリング（無効化）
		};
		r_layer16_w {
			layers = <ADJW>; // レイヤー16がアクティブな場合
			input-processors = <&zip_keybind_keys_ecad_radjw>; // zip_keybind_keys_ecad_radjw を使用
			process-next; // 他のプロセッサも処理を継続
		};
		r_layer16_w-prevent {
			layers = <ADJW>; // レイヤー16がアクティブな場合
			input-processors = <&zip_xy_scaler 0 1>; // ジョイスティックの動きをゼロにスケーリング（無効化）
		};
		r_mouse_speed_full_l {
			layers = <ADJL>; // レイヤー15がアクティブな場合
			input-processors = <&zip_xy_transform (0)> // 変換なし (Y軸反転を無効化)
							, <&zip_xy_scaler 80 100>; // 速度を80/100に設定 (乗数80, 除数100)
		};
		r_mouse_speed_full {
			layers = <ADJ>; // レイヤー14がアクティブな場合
			input-processors = <&zip_xy_transform (0)> // 変換なし (Y軸反転を無効化)
							, <&zip_xy_scaler 80 100>; // 速度を80/100に設定 (乗数80, 除数100)
		};
		r_layer13 {
			layers = <RSEW>; // レイヤー13がアクティブな場合
			input-processors = <&zip_keybind_keys_ecad_rsew>; // zip_keybind_keys_ecad_rsew を使用
			process-next; // 他のプロセッサも処理を継続
		};
		r_layer13-prevent {
			layers = <RSEW>; // レイヤー13がアクティブな場合
			input-processors = <&zip_xy_scaler 0 1>; // ジョイスティックの動きをゼロにスケーリング（無効化）
		};
		r_layer12_l {
			layers = <RSEL>; // レイヤー12がアクティブな場合
			input-processors = <&zip_keybind_keys_directionM>; // zip_keybind_keys_directionM を使用
			process-next; // 他のプロセッサも処理を継続
		};
		r_layer12_l-prevent {
			layers = <RSEL>; // レイヤー12がアクティブな場合
			input-processors = <&zip_xy_scaler 0 1>; // ジョイスティックの動きをゼロにスケーリング（無効化）
		};
		r_layer11 {
			layers = <RSE>; // レイヤー11がアクティブな場合
			input-processors = <&zip_keybind_keys_directionM>; // zip_keybind_keys_directionM を使用
			process-next; // 他のプロセッサも処理を継続
		};
		r_layer11-prevent {
			layers = <RSE>; // レイヤー11がアクティブな場合
			input-processors = <&zip_xy_scaler 0 1>; // ジョイスティックの動きをゼロにスケーリング（無効化）
		};
		r_scroll_w {
			layers = <LWRW>; // レイヤー10がアクティブな場合
			input-processors = <&zip_xy_transform (INPUT_TRANSFORM_Y_INVERT)>
							, <&zip_xy_scaler 18 100> // スケーリング（18/100）
							, <&zip_xy_to_scroll_mapper>; // スクロールイベントにマッピング
		};
		r_scroll_l {
			layers = <LWRL>; // レイヤー9がアクティブな場合
			input-processors = <&zip_xy_transform (INPUT_TRANSFORM_Y_INVERT)>
							, <&zip_xy_scaler 18 100> // スケーリング（18/100）
							, <&zip_xy_to_scroll_mapper>; // スクロールイベントにマッピング
		};
		r_scroll {
			layers = <LWR>; // レイヤー8がアクティブな場合
			input-processors = <&zip_xy_transform (INPUT_TRANSFORM_Y_INVERT)>
							, <&zip_xy_scaler 8 100> // スケーリング（8/100）
							, <&zip_xy_to_scroll_mapper>; // スクロールイベントにマッピング
		};
		r_layer7 {
			layers = <WIN>; // レイヤー7がアクティブな場合
			input-processors = <&zip_keybind_keys_directionL>; // zip_keybind_keys_directionL を使用
			process-next;
		};
		r_layer7-prevent {
			layers = <WIN>; // レイヤー7がアクティブな場合
			input-processors = <&zip_xy_scaler 0 1>; // ジョイスティックの動きをゼロにスケーリング（無効化）
		};
		r_cad {
			layers = <CAD>; // レイヤー6がアクティブな場合
			input-processors = <&zip_keybind_keys_directionH>; // zip_keybind_keys_directionH を使用
			process-next;
		};
		r_cad-prevent {
			layers = <CAD>; // レイヤー6がアクティブな場合
			input-processors = <&zip_xy_scaler 0 1>; // ジョイスティックの動きをゼロにスケーリング（無効化）
		};
		r_nicl {
			layers = <NICL>; // レイヤー5がアクティブな場合
			input-processors = <&zip_xy_transform (INPUT_TRANSFORM_Y_INVERT)>
							, <&zip_xy_scaler 16 100> // スケーリング（16/100）
							, <&zip_xy_to_scroll_mapper>; // スクロールイベントにマッピング
		};
		r_ngnl {
			layers = <NGNL>; // レイヤー4がアクティブな場合
			input-processors = <&zip_xy_transform (INPUT_TRANSFORM_Y_INVERT)>
							, <&zip_xy_scaler 16 100> // スケーリング（16/100）
							, <&zip_xy_to_scroll_mapper>; // スクロールイベントにマッピング
		};
		r_lin {
			layers = <LIN>; // レイヤー3がアクティブな場合
			input-processors = <&zip_xy_transform (INPUT_TRANSFORM_Y_INVERT)>
							, <&zip_xy_scaler 12 100> // スケーリング（12/100）
							, <&zip_xy_to_scroll_mapper>; // スクロールイベントにマッピング
		};
		// r_nic {
		// 	layers = <NIC>; // レイヤー2がアクティブな場合
		// 	input-processors = <&zip_xy_transform (INPUT_TRANSFORM_Y_INVERT)>
		// 					, <&zip_xy_scaler 8 100> // スケーリング（8/100）
		// 					, <&zip_xy_to_scroll_mapper>; // スクロールイベントにマッピング
		// };
		r_nic-prevent {
			layers = <NIC>; // レイヤー2がアクティブな場合
			input-processors = <&zip_xy_scaler 0 1>; // ジョイスティックの動きをゼロにスケーリング（無効化）
		};
		r_ngn {
			layers = <NGN>; // レイヤー1がアクティブな場合
			input-processors = <&zip_xy_transform (INPUT_TRANSFORM_Y_INVERT)>
							, <&zip_xy_scaler 5 100> // スケーリング（5/100）
							, <&zip_xy_to_scroll_mapper>; // スクロールイベントにマッピング
		};
		r_default {
			layers = <QWE>; // レイヤー0（デフォルト）がアクティブな場合
			input-processors = <&zip_xy_transform (INPUT_TRANSFORM_Y_INVERT)>
							, <&zip_xy_scaler 4 100> // スケーリング（4/100）
							, <&zip_xy_to_scroll_mapper>; // スクロールイベントにマッピング
		};
};

&kscan0 {
	col-gpios
		= <&gpio0 9 GPIO_ACTIVE_HIGH>
		, <&gpio0 10 GPIO_ACTIVE_HIGH>
		, <&xiao_d 2 GPIO_ACTIVE_HIGH>
		, <&xiao_d 3 GPIO_ACTIVE_HIGH>
		, <&xiao_d 4 GPIO_ACTIVE_HIGH>
		, <&xiao_d 5 GPIO_ACTIVE_HIGH>
		;
};
